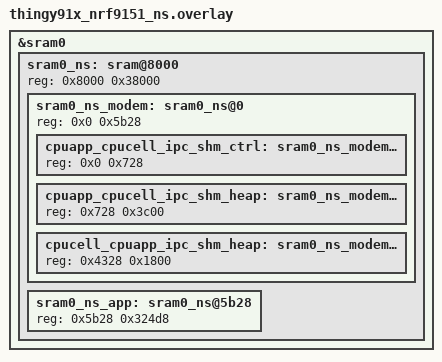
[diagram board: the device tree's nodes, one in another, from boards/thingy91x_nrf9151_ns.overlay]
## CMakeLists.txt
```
#
# Copyright (c) 2024 Nordic Semiconductor
#
# SPDX-License-Identifier: LicenseRef-Nordic-5-Clause
#

cmake_minimum_required(VERSION 3.20.0)

find_package(Zephyr REQUIRED HINTS $ENV{ZEPHYR_BASE})
project(DESH)
target_include_directories(app PRIVATE src)

target_sources(app PRIVATE src/main.c)
target_sources(app PRIVATE src/shell.c)

add_subdirectory(src/print)
add_subdirectory(src/utils)
add_subdirectory_ifdef(CONFIG_DESH_DECT_PHY src/dect)
add_subdirectory_ifdef(CONFIG_DESH_STARTUP_CMDS src/startup_cmd)
```

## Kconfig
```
#
# Copyright (c) 2024 Nordic Semiconductor ASA
#
# SPDX-License-Identifier: LicenseRef-Nordic-5-Clause
#

source "Kconfig.zephyr"

menu "Nordic Dect NR+ Phy Shell config"

config DESH_PRINT_BUFFER_SIZE
	int "Buffer size used when printing shell output"
	default 1024
	help
	  If the printed string exceeds this buffer, an error message is printed first and
	  then the requested string cut into the length of this buffer.

config DESH_DECT_PHY
	bool "DECT NR+ PHY api shell tools"
	default y
	help
	  DECT NR+ PHY api shell tools

config DESH_STARTUP_CMDS
	bool "Possibility to run stored shell commands from settings after bootup"
	default y

endmenu
```

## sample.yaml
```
sample:
  name: DECT NR+ PHY Shell sample
tests:
  sample.dect.dect_phy.dect_shell:
    sysbuild: true
    build_only: true
    integration_platforms:
      - nrf9151dk/nrf9151/ns
      - thingy91x/nrf9151/ns
    platform_allow:
      - nrf9151dk/nrf9151/ns
      - thingy91x/nrf9151/ns
    tags:
      - ci_build
      - sysbuild
      - ci_samples_dect
```

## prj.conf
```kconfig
CONFIG_NRF_MODEM_LINK_BINARY_DECT_PHY=y
CONFIG_DESH_DECT_PHY=y
#To bypass error print from Modem Antenna Lib because dect mfw does not support this
CONFIG_MODEM_ANTENNA_AT_COEX0=""

# Faster random data generation for rf_tool payload data
CONFIG_XOSHIRO_RANDOM_GENERATOR=y

# Shell configurations
CONFIG_SHELL=y
CONFIG_SHELL_WILDCARD=n
CONFIG_SHELL_PROMPT_UART="desh:~$ "
CONFIG_SHELL_ARGC_MAX=40

# Note that NR+ modem FW supports a limited set of AT commands
CONFIG_AT_SHELL=y

# -h and --help options are handled in Dect Shell
CONFIG_SHELL_HELP_OPT_PARSE=n
CONFIG_SHELL_CMD_BUFF_SIZE=1024
# Shell stack has most impact for DECT shell application, not CONFIG_MAIN_STACK_SIZE
CONFIG_SHELL_STACK_SIZE=9216
# Main stack size need to be increased due to CONFIG_NRF_MODEM_LIB_TRACE
CONFIG_MAIN_STACK_SIZE=2048

# Shell RX buffer needs to be increased to avoid problems with test automation
CONFIG_SHELL_BACKEND_SERIAL_RX_RING_BUFFER_SIZE=512
# Use interrupt driven shell UART, otherwise we won't be able to suspend the UART
CONFIG_SHELL_BACKEND_SERIAL_API_INTERRUPT_DRIVEN=y

# Enable use of vsnprintfcb() for extending desh_print() format
CONFIG_CBPRINTF_LIBC_SUBSTS=y

CONFIG_COMMON_LIBC_MALLOC=n

CONFIG_FPU=y

CONFIG_GETOPT_LONG=y

CONFIG_DK_LIBRARY=y
CONFIG_AT_MONITOR=y
CONFIG_MODEM_ANTENNA=y

CONFIG_ISR_STACK_SIZE=4096
CONFIG_HEAP_MEM_POOL_SIZE=40960
CONFIG_SYSTEM_WORKQUEUE_STACK_SIZE=512
CONFIG_SHELL_CMD_BUFF_SIZE=1024
CONFIG_AT_MONITOR_HEAP_SIZE=512

# Settings
CONFIG_FLASH=y
CONFIG_FLASH_MAP=y
CONFIG_MPU_ALLOW_FLASH_WRITE=y
CONFIG_NVS=y
CONFIG_SETTINGS=y
CONFIG_SETTINGS_NVS=y
CONFIG_NVS_LOG_LEVEL_WRN=y

# Kernel options
CONFIG_ENTROPY_GENERATOR=y
#CONFIG_REBOOT=y

# Modem library
CONFIG_NRF_MODEM_LIB=y
CONFIG_NRF_MODEM_LIB_ON_FAULT_APPLICATION_SPECIFIC=y

# Debugging configurations
CONFIG_ASSERT=y
CONFIG_LOG=y

# Keep printk() synchronous
CONFIG_PRINTK=y
CONFIG_LOG_PRINTK=n

#CONFIG_DEBUG_OPTIMIZATIONS=y
#CONFIG_NO_OPTIMIZATIONS=y
#CONFIG_FORCE_NO_ASSERT=y
CONFIG_ASSERT_MODULE_DEFAULT_LEVEL_VERBOSE=y
#CONFIG_ASSERT_LEVEL=2
#CONFIG_ASSERT_ON_ERRORS=y
#CONFIG_FAULT_DUMP=2
CONFIG_RESET_ON_FATAL_ERROR=n
CONFIG_EXTRA_EXCEPTION_INFO=y
#CONFIG_WATCHDOG=y
CONFIG_SYS_HEAP_RUNTIME_STATS=y

CONFIG_TFM_PROFILE_TYPE_MINIMAL=y
# Enable TF-M logging on UART0
CONFIG_TFM_SECURE_UART0=y
CONFIG_TFM_LOG_LEVEL_SILENCE=n
CONFIG_TFM_EXCEPTION_INFO_DUMP=y
CONFIG_TFM_SPM_LOG_LEVEL_DEBUG=y
```

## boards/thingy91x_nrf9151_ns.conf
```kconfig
#
# Copyright (c) 2024 Nordic Semiconductor ASA
#
# SPDX-License-Identifier: LicenseRef-Nordic-5-Clause
#

# Configuration file for Thingy:91 X.
# This file is merged with prj.conf in the application folder, and options
# set here will take precedence if they are present in both files.

# MCUBOOT
CONFIG_IMG_MANAGER=y
CONFIG_STREAM_FLASH=y
CONFIG_MCUBOOT_IMG_MANAGER=y
CONFIG_IMG_ERASE_PROGRESSIVELY=y
```

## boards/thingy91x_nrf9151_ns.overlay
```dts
/*
 * Copyright (c) 2026 Nordic Semiconductor ASA
 *
 * SPDX-License-Identifier: LicenseRef-Nordic-5-Clause
 */

/delete-node/ &sram0_ns;

&sram0 {
	/*
	 * 0x2000_0000  Secure RAM                      (   32 kB)
	 * 0x2000_8000  Non-secure RAM area             (  224 kB)
	 *   0x2000_8000  Modem shared area             ( 23336 B)
	 *     0x2000_8000  control                     (  1832 B)
	 *     0x2000_8728  app -> cell                 (   15 kB)
	 *     0x2000_c328  cell -> app                 (    6 kB)
	 *   0x2000_db28  Application RAM               (206040 B)
	 */

	sram0_ns: sram@8000 {
		reg = <0x8000 0x38000>;
		#address-cells = <1>;
		#size-cells = <1>;
		ranges = <0x0 0x8000 0x38000>;

		/* Must be in first 128 kB of RAM. */
		sram0_ns_modem: sram0_ns@0 {
			/* Modem (shared) memory */
			reg = <0x0 0x5b28>;
			#address-cells = <1>;
			#size-cells = <1>;
			ranges = <0x0 0x0 0x5b28>;

			cpuapp_cpucell_ipc_shm_ctrl: sram0_ns_modem@0 {
				/* Modem IPC control */
				reg = <0x0 0x728>;
			};

			cpuapp_cpucell_ipc_shm_heap: sram0_ns_modem@728 {
				/* Modem IPC transmit */
				reg = <0x728 0x3c00>;
			};

			cpucell_cpuapp_ipc_shm_heap: sram0_ns_modem@4328 {
				/* Modem IPC receive */
				reg = <0x4328 0x1800>;
			};
		};

		sram0_ns_app: sram0_ns@5b28 {
			/* Non-Secure application memory */
			reg = <0x5b28 0x324d8>;
		};
	};
};
```

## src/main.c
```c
/*
 * Copyright (c) 2024 Nordic Semiconductor ASA
 *
 * SPDX-License-Identifier: LicenseRef-Nordic-5-Clause
 */

#include <stdio.h>
#include <string.h>

#include <zephyr/kernel.h>
#include <zephyr/init.h>
#include <helpers/nrfx_reset_reason.h>
#include <nrf_modem.h>

#include <sys/types.h>
#include <zephyr/logging/log_ctrl.h>
#include <zephyr/sys/reboot.h>
#include <zephyr/dfu/mcuboot.h>

#include <zephyr/shell/shell.h>
#include <zephyr/shell/shell_uart.h>

#include <modem/nrf_modem_lib.h>
#include <modem/nrf_modem_lib_trace.h>

#include <dk_buttons_and_leds.h>

#if defined(CONFIG_DESH_STARTUP_CMDS)
#include "startup_cmd_ctrl.h"
#endif
#include "desh_defines.h"
#include "desh_print.h"

BUILD_ASSERT(IS_ENABLED(CONFIG_SHELL_BACKEND_SERIAL),
	     "CONFIG_SHELL_BACKEND_SERIAL shell backend must be enabled");

/***** Work queue and work item definitions *****/

#if defined(CONFIG_DESH_STARTUP_CMDS)
#define DESH_COMMON_WORKQUEUE_STACK_SIZE 4096
#define DESH_COMMON_WORKQ_PRIORITY 5
K_THREAD_STACK_DEFINE(desh_common_workq_stack, DESH_COMMON_WORKQUEUE_STACK_SIZE);
struct k_work_q desh_common_work_q;
#endif

/* Global variables */
const struct shell *desh_shell;

char desh_at_resp_buf[DESH_AT_CMD_RESPONSE_MAX_LEN];
K_MUTEX_DEFINE(desh_at_resp_buf_mutex);

static const char *modem_crash_reason_get(uint32_t reason)
{
	switch (reason) {
	case NRF_MODEM_FAULT_UNDEFINED:
		return "Undefined fault";

	case NRF_MODEM_FAULT_HW_WD_RESET:
		return "HW WD reset";

	case NRF_MODEM_FAULT_HARDFAULT:
		return "Hard fault";

	case NRF_MODEM_FAULT_MEM_MANAGE:
		return "Memory management fault";

	case NRF_MODEM_FAULT_BUS:
		return "Bus fault";

	case NRF_MODEM_FAULT_USAGE:
		return "Usage fault";

	case NRF_MODEM_FAULT_SECURE_RESET:
		return "Secure control reset";

	case NRF_MODEM_FAULT_PANIC_DOUBLE:
		return "Error handler crash";

	case NRF_MODEM_FAULT_PANIC_RESET_LOOP:
		return "Reset loop";

	case NRF_MODEM_FAULT_ASSERT:
		return "Assert";

	case NRF_MODEM_FAULT_PANIC:
		return "Unconditional SW reset";

	case NRF_MODEM_FAULT_FLASH_ERASE:
		return "Flash erase fault";

	case NRF_MODEM_FAULT_FLASH_WRITE:
		return "Flash write fault";

	case NRF_MODEM_FAULT_POFWARN:
		return "Undervoltage fault";

	case NRF_MODEM_FAULT_THWARN:
		return "Overtemperature fault";

	default:
		return "Unknown reason";
	}
}

void nrf_modem_fault_handler(struct nrf_modem_fault_info *fault_info)
{
	printk("Modem crash reason: 0x%x (%s), PC: 0x%x\n",
		fault_info->reason,
		modem_crash_reason_get(fault_info->reason),
		fault_info->program_counter);

	__ASSERT(false, "Modem crash detected, halting application execution");
}

static void reset_reason_str_get(char *str, uint32_t reason)
{
	size_t len;

	*str = '\0';

	if (reason & NRFX_RESET_REASON_RESETPIN_MASK) {
		(void)strcat(str, "PIN reset | ");
	}
	if (reason & NRFX_RESET_REASON_DOG_MASK) {
		(void)strcat(str, "watchdog | ");
	}
	if (reason & NRFX_RESET_REASON_OFF_MASK) {
		(void)strcat(str, "wakeup from power-off | ");
	}
	if (reason & NRFX_RESET_REASON_DIF_MASK) {
		(void)strcat(str, "debug interface wakeup | ");
	}
	if (reason & NRFX_RESET_REASON_SREQ_MASK) {
		(void)strcat(str, "software | ");
	}
	if (reason & NRFX_RESET_REASON_LOCKUP_MASK) {
		(void)strcat(str, "CPU lockup | ");
	}
	if (reason & NRFX_RESET_REASON_CTRLAP_MASK) {
		(void)strcat(str, "control access port | ");
	}

	len = strlen(str);
	if (len == 0) {
		(void)strcpy(str, "power-on reset");
	} else {
		str[len - 3] = '\0';
	}
}

static void desh_print_reset_reason(void)
{
	uint32_t reset_reason;
	char reset_reason_str[128];

	/* Read RESETREAS register value and clear current reset reason(s). */
	reset_reason = nrfx_reset_reason_get();
	nrfx_reset_reason_clear(reset_reason);

	reset_reason_str_get(reset_reason_str, reset_reason);

	printk("\nReset reason: %s\n", reset_reason_str);
}

int main(void)
{
	int err;

	desh_shell = shell_backend_uart_get_ptr();

	__ASSERT(desh_shell != NULL, "Failed to get shell backend");

	/* Reset reason can only be read once, because the register needs to be cleared after
	 * reading.
	 */
	desh_print_reset_reason();

#if defined(CONFIG_DESH_STARTUP_CMDS)
	struct k_work_queue_config cfg = {
		.name = "desh_common_workq",
	};

	k_work_queue_start(
		&desh_common_work_q,
		desh_common_workq_stack,
		K_THREAD_STACK_SIZEOF(desh_common_workq_stack),
		DESH_COMMON_WORKQ_PRIORITY,
		&cfg);
#endif
	err = nrf_modem_lib_init();
	if (err) {
		/* Modem library initialization failed. */
		printk("Could not initialize nrf_modem_lib, err %d\n", err);
		printk("Fatal error\n");
		return 0;
	}
#if defined(CONFIG_DESH_STARTUP_CMDS)
	startup_cmd_ctrl_init();
#endif
#if defined(CONFIG_DK_LIBRARY)
	err = dk_leds_init();
	if (err) {
		printk("Cannot initialize LEDs (err: %d)\n", err);
	}
#endif

	/* Resize terminal width and height of the shell to have proper command editing. */
	shell_execute_cmd(desh_shell, "resize");

	desh_print_version_info();

	return 0;
}
```

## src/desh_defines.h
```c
/*
 * Copyright (c) 2024 Nordic Semiconductor ASA
 *
 * SPDX-License-Identifier: LicenseRef-Nordic-5-Clause
 */

#ifndef DESH_DEFINES_H
#define DESH_DEFINES_H

#define DESH_EMPTY_STRING "\0"

#define DESH_STRING_NULL_CHECK(string) \
	((string != NULL) ? string : DESH_EMPTY_STRING)

#define DESH_AT_CMD_RESPONSE_MAX_LEN 2701

#endif /* DESH_DEFINES_H */
```

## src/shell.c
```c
/*
 * Copyright (c) 2024 Nordic Semiconductor ASA
 *
 * SPDX-License-Identifier: LicenseRef-Nordic-5-Clause
 */

#include <stdlib.h>
#include <malloc.h>

#include <zephyr/kernel.h>
#include <zephyr/device.h>
#include <zephyr/sys/sys_heap.h>
#include <zephyr/linker/linker-defs.h>
#include <zephyr/shell/shell.h>
#include <modem/nrf_modem_lib.h>

#include "desh_print.h"

extern struct k_poll_signal desh_signal;

int sleep_shell(const struct shell *shell, size_t argc, char **argv)
{
	long sleep_duration = strtol(argv[1], NULL, 10);

	if (sleep_duration > 0) {
		k_sleep(K_SECONDS(sleep_duration));
		return 0;
	}
	desh_print("sleep: duration must be greater than zero");

	return -EINVAL;
}

#if defined(CONFIG_SYS_HEAP_RUNTIME_STATS)
extern struct sys_heap _system_heap;
#endif

int heap_shell(const struct shell *shell, size_t argc, char **argv)
{
	struct mallinfo system_stats;

#if defined(CONFIG_SYS_HEAP_RUNTIME_STATS)
	int err;
	struct sys_memory_stats kernel_stats;

	err = sys_heap_runtime_stats_get(&_system_heap, &kernel_stats);
	if (err) {
		desh_error("heap: failed to read kernel heap statistics, error: %d", err);
	} else {
		desh_print("kernel heap statistics:");
		desh_print("free:           %6d", kernel_stats.free_bytes);
		desh_print("allocated:      %6d", kernel_stats.allocated_bytes);
		desh_print("max. allocated: %6d\n", kernel_stats.max_allocated_bytes);
	}
#endif /* CONFIG_SYS_HEAP_RUNTIME_STATS */

	/* Calculate the system heap maximum size. */
#define USED_RAM_END_ADDR POINTER_TO_UINT(&_end)
#define HEAP_BASE USED_RAM_END_ADDR
#define MAX_HEAP_SIZE (KB(CONFIG_SRAM_SIZE) - (HEAP_BASE - CONFIG_SRAM_BASE_ADDRESS))

	system_stats = mallinfo();

	desh_print("system heap statistics:");
	desh_print("max. size:      %6d", MAX_HEAP_SIZE);
	desh_print("size:           %6d", system_stats.arena);
	desh_print("free:           %6d", system_stats.fordblks);
	desh_print("allocated:      %6d", system_stats.uordblks);

	return 0;
}

int version_shell(const struct shell *shell, size_t argc, char **argv)
{
	desh_print_version_info();

	return 0;
}

SHELL_CMD_ARG_REGISTER(sleep, NULL,
	"Sleep for n seconds.",
	sleep_shell, 2, 0);

SHELL_CMD_ARG_REGISTER(heap, NULL,
	"Print heap usage statistics.",
	heap_shell, 1, 0);

SHELL_CMD_ARG_REGISTER(version, NULL,
	"Print application version information.",
	version_shell, 1, 0);
```
